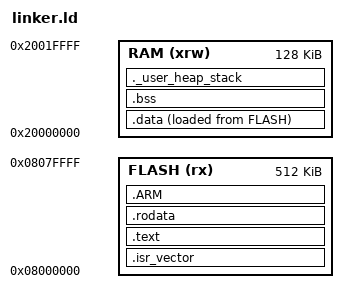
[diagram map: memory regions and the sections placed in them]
ENTRY(Reset_Handler)

MEMORY
{
  RAM    (xrw)    : ORIGIN = 0x20000000,   LENGTH = 128K
  FLASH   (rx)    : ORIGIN = 0x08000000,   LENGTH = 512K
}

_estack = ORIGIN(RAM) + LENGTH(RAM);
_Min_Heap_Size = 0x200; /* required amount of heap */
_Min_Stack_Size = 0x400; /* required amount of stack */

SECTIONS
{
    .isr_vector :
    {
        . = ALIGN(4);
        KEEP(*(.isr_vector)) /* Startup code */
        . = ALIGN(4);
    } >FLASH

    .text :
    {
        . = ALIGN(4);
        *(.text)
        *(.text*)
        *(.glue_7)         /* glue arm to thumb code */
        *(.glue_7t)        /* glue thumb to arm code */
        *(.eh_frame)
        KEEP (*(.init))
        KEEP (*(.fini))
        . = ALIGN(4);
        _etext = .;
    } >FLASH

    .rodata :
    {
        . = ALIGN(4);
        *(.rodata)
        *(.rodata*)
        . = ALIGN(4);
    } >FLASH

    .ARM : {
        . = ALIGN(4);
        __exidx_start = .;
        *(.ARM.exidx*)
        __exidx_end = .;
        . = ALIGN(4);
    } >FLASH

    _lddata = LOADADDR(.data);
    .data :
    {
        . = ALIGN(4);
        _sdata = .;
        *(.data)
        *(.data*)
        . = ALIGN(4);
        _edata = .;
    } >RAM AT> FLASH

    .bss :
    {
        . = ALIGN(4);
        _sbss = .;
        __bss_start__ = _sbss;
        *(.bss)
        *(.bss.*)
        *(COMMON)
        . = ALIGN(4);
        _ebss = .;
        __bss_end__ = _ebss;
    } >RAM

    ._user_heap_stack :
    {
        . = ALIGN(8);
        end = .;
        _end = .;
        __end__ = .;
        . = . + _Min_Heap_Size;
        . = . + _Min_Stack_Size;
        . = ALIGN(8);
    } >RAM

    /* Remove information from the compiler libraries */
    /DISCARD/ :
    {
        libc.a ( * )
        libm.a ( * )
        libgcc.a ( * )
    }

    .ARM.attributes 0 : { *(.ARM.attributes) }
}
